# MSP430F249 register map
Vendor: msp430gen; File version: v0.4.0
Registers are 8-bit, read-write, reset 0x0 unless marked. A register's access mark holds for its fields unless they carry their own. Offsets are from the block's base; [hi:lo] are bit positions; lines under a group give offsets from that group; {n}, {i} and the like mark numbered series.

## USCI_B1_SPI_MODE
Base 0x000000D8
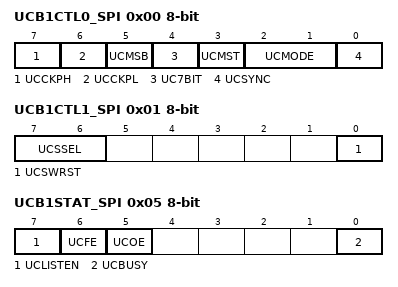
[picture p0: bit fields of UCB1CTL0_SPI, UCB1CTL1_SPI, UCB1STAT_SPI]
0x00 UCB1CTL0_SPI — USCI B1 Control Register 0
  [7] UCCKPH — Sync. Mode: Clock Phase
  [6] UCCKPL — Sync. Mode: Clock Polarity
  [5] UCMSB — Sync. Mode: MSB first 0:LSB / 1:MSB
  [4] UC7BIT — Sync. Mode: Data Bits 0:8-bits / 1:7-bits
  [3] UCMST — Sync. Mode: Master Select
  [2:1] UCMODE — Sync. Mode: USCI Mode 1
    {v}=Sync. Mode: USCI Mode: {v} (v=0..3)
  [0] UCSYNC — Sync-Mode 0:UART-Mode / 1:SPI-Mode
0x01 UCB1CTL1_SPI — USCI B1 Control Register 1
  [7:6] UCSSEL — USCI 1 Clock Source Select 1
    {v}=USCI 0 Clock Source: {v} (v=0..3)
  [0] UCSWRST — USCI Software Reset
0x02 UCB1BR0_SPI — USCI B1 Baud Rate 0
0x03 UCB1BR1_SPI — USCI B1 Baud Rate 1
0x05 UCB1STAT_SPI — USCI B1 Status Register
  [7] UCLISTEN — USCI Listen mode
  [6] UCFE — USCI Frame Error Flag
  [5] UCOE — USCI Overrun Error Flag
  [0] UCBUSY — USCI Busy Flag
0x06 UCB1RXBUF_SPI — USCI B1 Receive Buffer
0x07 UCB1TXBUF_SPI — USCI B1 Transmit Buffer

## TLV_CALIBRATION_DATA
Base 0x000010C0
0x00 TLV_CHECKSUM 16-bit
0x1A TLV_ADC12_1_TAG
0x1B TLV_ADC12_1_LEN
0x36 TLV_DCO_30_TAG — TLV TAG_DCO30 TAG
0x37 TLV_DCO_30_LEN — TLV TAG_DCO30 LEN

## CALIBRATION_DATA
Base 0x000010F8
0x00 CALDCO_16MHZ — DCOCTL Calibration Data for 16MHz
0x01 CALBC1_16MHZ — BCSCTL1 Calibration Data for 16MHz
0x02 CALDCO_12MHZ — DCOCTL Calibration Data for 12MHz
0x03 CALBC1_12MHZ — BCSCTL1 Calibration Data for 12MHz
0x04 CALDCO_8MHZ — DCOCTL Calibration Data for 8MHz
0x05 CALBC1_8MHZ — BCSCTL1 Calibration Data for 8MHz
0x06 CALDCO_1MHZ — DCOCTL Calibration Data for 1MHz
0x07 CALBC1_1MHZ — BCSCTL1 Calibration Data for 1MHz

## TIMER_B7
Base 0x0000011E
0x00 TBIV 16-bit — Timer B Interrupt Vector Word
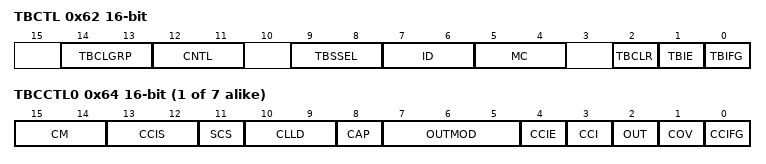
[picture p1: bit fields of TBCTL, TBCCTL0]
0x62 TBCTL 16-bit — Timer B Control
  [14:13] TBCLGRP — Timer B Compare latch load group 1
    0=Timer B Group: 0 - individually; 1=Timer B Group: 1 - 3 groups (1-2; 2=Timer B Group: 2 - 2 groups (1-3; 3=Timer B Group: 3 - 1 group (all)
  [12:11] CNTL — Counter lenght 1
    0=Counter lenght: 16 bit; 1=Counter lenght: 12 bit; 2=Counter lenght: 10 bit; 3=Counter lenght: 8 bit
  [9:8] TBSSEL — Clock source 1
    0=Clock Source: TBCLK; 1=Clock Source: ACLK; 2=Clock Source: SMCLK; 3=Clock Source: INCLK
  [7:6] ID — Timer B clock input divider 1
    0=Timer A input divider: 0 - /1; 1=Timer A input divider: 1 - /2; 2=Timer A input divider: 2 - /4; 3=Timer A input divider: 3 - /8
  [5:4] MC — Timer B mode control 1
    0=Timer A mode control: 0 - Stop; 1=Timer A mode control: 1 - Up to CCR0; 2=Timer A mode control: 2 - Continous up; 3=Timer A mode control: 3 - Up/Down
  [2] TBCLR — Timer B counter clear
  [1] TBIE — Timer B interrupt enable
  [0] TBIFG — Timer B interrupt flag
{0x64+2i} TBCCTL{i} 16-bit (i=0..6) — Timer B Capture/Compare Control {i}
  [15:14] CM — Capture mode 1
    0=Capture mode: 0 - disabled; 1=Capture mode: 1 - pos. edge; 2=Capture mode: 1 - neg. edge; 3=Capture mode: 1 - both edges
  [13:12] CCIS — Capture input select 1
    0=Capture input select: 0 - CCIxA; 1=Capture input select: 1 - CCIxB; 2=Capture input select: 2 - GND; 3=Capture input select: 3 - Vcc
  [11] SCS — Capture sychronize
  [10:9] CLLD — Compare latch load source 1
    0=Compare latch load sourec : 0 - immediate; 1=Compare latch load sourec : 1 - TBR counts to 0; 2=Compare latch load sourec : 2 - up/down; 3=Compare latch load sourec : 3 - TBR counts to TBCTL0
  [8] CAP — Capture mode: 1 /Compare mode : 0
  [7:5] OUTMOD — Output mode 2
    0=PWM output mode: 0 - output only; 1=PWM output mode: 1 - set; 2=PWM output mode: 2 - PWM toggle/reset; 3=PWM output mode: 3 - PWM set/reset; 4=PWM output mode: 4 - toggle; 5=PWM output mode: 5 - Reset; 6=PWM output mode: 6 - PWM toggle/set; 7=PWM output mode: 7 - PWM reset/set
  [4] CCIE — Capture/compare interrupt enable
  [3] CCI — Capture input signal (read)
  [2] OUT — PWM Output signal if output mode 0
  [1] COV — Capture/compare overflow flag
  [0] CCIFG — Capture/compare interrupt flag
0x72 TBR 16-bit — Timer B Counter Register
{0x74+2i} TBCCR{i} 16-bit (i=0..6) — Timer B Capture/Compare {i}
